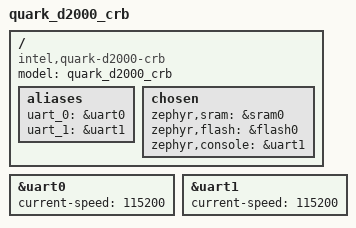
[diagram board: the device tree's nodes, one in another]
/dts-v1/;

#include "intel_quark_d2000.dtsi"

/ {
	model = "quark_d2000_crb";
	compatible = "intel,quark-d2000-crb", "intel,quark-d2000";

	aliases {
		uart_0 = &uart0;
		uart_1 = &uart1;
	};

	chosen {
		zephyr,sram = &sram0;
		zephyr,flash = &flash0;
		zephyr,console = &uart1;
	};
};

&uart0 {
	status = "ok";
	current-speed = <115200>;
};

&uart1 {
	status = "ok";
	current-speed = <115200>;
};
